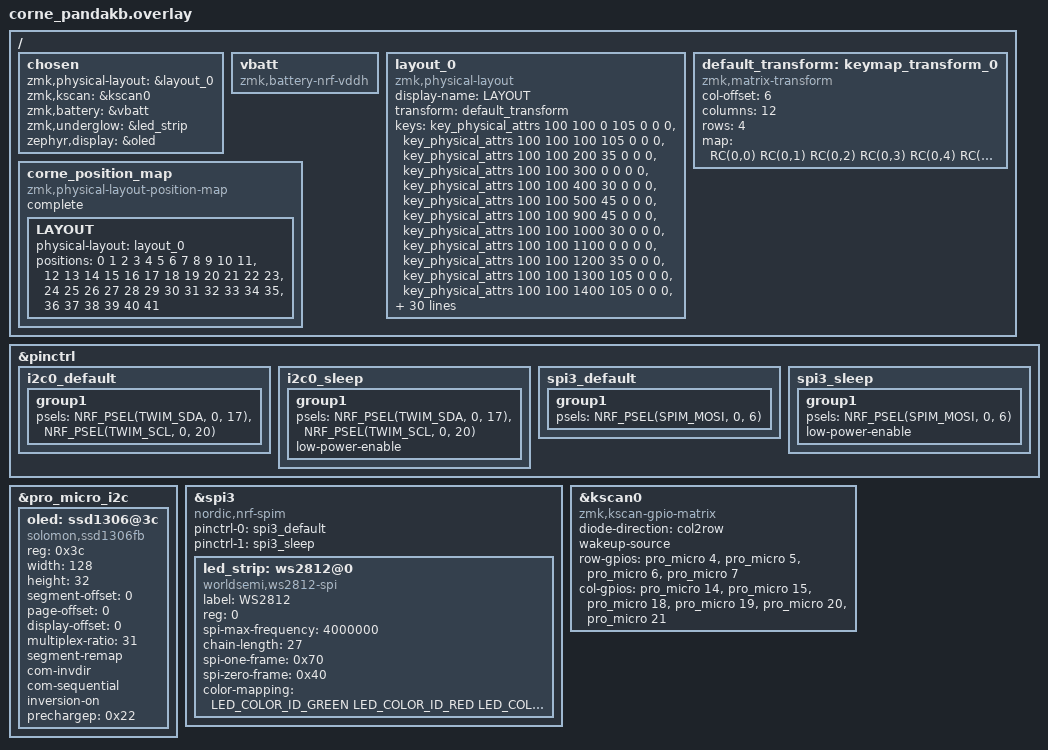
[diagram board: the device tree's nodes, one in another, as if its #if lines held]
#include <dt-bindings/zmk/matrix_transform.h>
#include <dt-bindings/led/led.h>

#ifdef SHIELD_CORNE_LEFT || SHIELD_CORNE_RIGHT
// oled,I2c
&pinctrl {
	i2c0_default: i2c0_default {
		group1 {
			psels = <NRF_PSEL(TWIM_SDA, 0, 17)>,
				<NRF_PSEL(TWIM_SCL, 0, 20)>;
		};
	};

	i2c0_sleep: i2c0_sleep {
		group1 {
			psels = <NRF_PSEL(TWIM_SDA, 0, 17)>,
				<NRF_PSEL(TWIM_SCL, 0, 20)>;
				low-power-enable;
		};
	};
};


&pro_micro_i2c {
	status = "okay";

	oled: ssd1306@3c {
		compatible = "solomon,ssd1306fb";
		reg = <0x3c>;
		width = <128>;
		height = <32>;
		segment-offset = <0>;
		page-offset = <0>;
		display-offset = <0>;
		multiplex-ratio = <31>;
		segment-remap;
		com-invdir;
		com-sequential;
		inversion-on;
		prechargep = <0x22>;
	};
};

// rgb,SPI
&pinctrl {
	spi3_default: spi3_default {
		group1 {
			psels = <NRF_PSEL(SPIM_MOSI, 0, 6)>;
		};
	};

	spi3_sleep: spi3_sleep {
		group1 {
			psels = <NRF_PSEL(SPIM_MOSI, 0, 6)>;
			low-power-enable;
		};
	};
};

&spi3 {
	compatible = "nordic,nrf-spim";
	status = "okay";

	pinctrl-0 = <&spi3_default>;
	pinctrl-1 = <&spi3_sleep>;
	pinctrl-names = "default", "sleep";


	led_strip: ws2812@0 {
		compatible = "worldsemi,ws2812-spi";
		label = "WS2812";

		/* SPI */
		reg = <0>; /* ignored, but necessary for SPI bindings */
		spi-max-frequency = <4000000>;

		/* WS2812 */
		chain-length = <27>; /* There are per-key RGB, but the first 6 are underglow */
		spi-one-frame = <0x70>;
		spi-zero-frame = <0x40>;
		color-mapping = <LED_COLOR_ID_GREEN LED_COLOR_ID_RED LED_COLOR_ID_BLUE>;
	};
};

&kscan0 {
	compatible = "zmk,kscan-gpio-matrix";
	diode-direction = "col2row";
	wakeup-source;

	row-gpios
	= <&pro_micro 4 (GPIO_ACTIVE_HIGH | GPIO_PULL_DOWN)>
	, <&pro_micro 5 (GPIO_ACTIVE_HIGH | GPIO_PULL_DOWN)>
	, <&pro_micro 6 (GPIO_ACTIVE_HIGH | GPIO_PULL_DOWN)>
	, <&pro_micro 7 (GPIO_ACTIVE_HIGH | GPIO_PULL_DOWN)>
	;

#ifdef SHIELD_CORNE_LEFT
	col-gpios
		= <&pro_micro 21 GPIO_ACTIVE_HIGH>
		, <&pro_micro 20 GPIO_ACTIVE_HIGH>
		, <&pro_micro 19 GPIO_ACTIVE_HIGH>
		, <&pro_micro 18 GPIO_ACTIVE_HIGH>
		, <&pro_micro 15 GPIO_ACTIVE_HIGH>
		, <&pro_micro 14 GPIO_ACTIVE_HIGH>
		;
#endif
#ifdef SHIELD_CORNE_RIGHT
	col-gpios
		= <&pro_micro 14	GPIO_ACTIVE_HIGH>
		, <&pro_micro 15	GPIO_ACTIVE_HIGH>
		, <&pro_micro 18	GPIO_ACTIVE_HIGH>
		, <&pro_micro 19	GPIO_ACTIVE_HIGH>
		, <&pro_micro 20	GPIO_ACTIVE_HIGH>
		, <&pro_micro 21	GPIO_ACTIVE_HIGH>
		;
#endif
};
#endif


/ {
	chosen {
		zmk,physical-layout = &layout_0;
#ifdef SHIELD_CORNE_LEFT || SHIELD_CORNE_RIGHT
		zmk,kscan = &kscan0;
		zmk,battery = &vbatt;
		zmk,underglow = &led_strip;
		zephyr,display = &oled;
#endif
	};

	vbatt: vbatt {
		compatible = "zmk,battery-nrf-vddh";
	};

	layout_0: layout_0 {
		compatible = "zmk,physical-layout";
		display-name = "LAYOUT";
		transform = <&default_transform>;

		keys  //                     w   h    x    y     rot    rx    ry
		= <&key_physical_attrs 100 100    0  105       0     0     0>
		, <&key_physical_attrs 100 100  100  105       0     0     0>
		, <&key_physical_attrs 100 100  200   35       0     0     0>
		, <&key_physical_attrs 100 100  300    0       0     0     0>
		, <&key_physical_attrs 100 100  400   30       0     0     0>
		, <&key_physical_attrs 100 100  500   45       0     0     0>
		, <&key_physical_attrs 100 100  900   45       0     0     0>
		, <&key_physical_attrs 100 100 1000   30       0     0     0>
		, <&key_physical_attrs 100 100 1100    0       0     0     0>
		, <&key_physical_attrs 100 100 1200   35       0     0     0>
		, <&key_physical_attrs 100 100 1300  105       0     0     0>
		, <&key_physical_attrs 100 100 1400  105       0     0     0>
		, <&key_physical_attrs 100 100    0  205       0     0     0>
		, <&key_physical_attrs 100 100  100  205       0     0     0>
		, <&key_physical_attrs 100 100  200  135       0     0     0>
		, <&key_physical_attrs 100 100  300  100       0     0     0>
		, <&key_physical_attrs 100 100  400  130       0     0     0>
		, <&key_physical_attrs 100 100  500  145       0     0     0>
		, <&key_physical_attrs 100 100  900  145       0     0     0>
		, <&key_physical_attrs 100 100 1000  130       0     0     0>
		, <&key_physical_attrs 100 100 1100  100       0     0     0>
		, <&key_physical_attrs 100 100 1200  135       0     0     0>
		, <&key_physical_attrs 100 100 1300  205       0     0     0>
		, <&key_physical_attrs 100 100 1400  205       0     0     0>
		, <&key_physical_attrs 100 100    0  305       0     0     0>
		, <&key_physical_attrs 100 100  100  305       0     0     0>
		, <&key_physical_attrs 100 100  200  235       0     0     0>
		, <&key_physical_attrs 100 100  300  200       0     0     0>
		, <&key_physical_attrs 100 100  400  230       0     0     0>
		, <&key_physical_attrs 100 100  500  245       0     0     0>
		, <&key_physical_attrs 100 100  900  245       0     0     0>
		, <&key_physical_attrs 100 100 1000  230       0     0     0>
		, <&key_physical_attrs 100 100 1100  200       0     0     0>
		, <&key_physical_attrs 100 100 1200  235       0     0     0>
		, <&key_physical_attrs 100 100 1300  305       0     0     0>
		, <&key_physical_attrs 100 100 1400  305       0     0     0>
		, <&key_physical_attrs 100 100  390  340       0     0     0>
		, <&key_physical_attrs 100 100  490  340    1300     0   425>
		, <&key_physical_attrs 100 100  590  360    2600     0   460>
		, <&key_physical_attrs 100 100  815  340 (-2600)   950   460>
		, <&key_physical_attrs 100 100  905  330 (-1300)  1050   425>
		, <&key_physical_attrs 100 100 1010  340       0     0     0>
		;
	};

	default_transform: keymap_transform_0 {
		compatible = "zmk,matrix-transform";
#ifdef SHIELD_CORNE_RIGHT
		col-offset = <6>;
#endif
		columns = <12>;
		rows = <4>;
// | SW1  | SW2  | SW3  | SW4  | SW5  | SW6  |   | SW6  | SW5  | SW4  | SW3  | SW2  | SW1  |
// | SW7  | SW8  | SW9  | SW10 | SW11 | SW12 |   | SW12 | SW11 | SW10 | SW9  | SW8  | SW7  |
// | SW13 | SW14 | SW15 | SW16 | SW17 | SW18 |   | SW18 | SW17 | SW16 | SW15 | SW14 | SW13 |
//                      | SW19 | SW20 | SW21 |   | SW21 | SW20 | SW19 |
		map = <
RC(0,0) RC(0,1) RC(0,2) RC(0,3) RC(0,4) RC(0,5)  RC(0,6)  RC(0,7) RC(0,8) RC(0,9) RC(0,10) RC(0,11)
RC(1,0) RC(1,1) RC(1,2) RC(1,3) RC(1,4) RC(1,5)  RC(1,6)  RC(1,7) RC(1,8) RC(1,9) RC(1,10) RC(1,11)
RC(2,0) RC(2,1) RC(2,2) RC(2,3) RC(2,4) RC(2,5)  RC(2,6)  RC(2,7) RC(2,8) RC(2,9) RC(2,10) RC(2,11)
                        RC(3,3) RC(3,4) RC(3,5)  RC(3,6) RC(3,7) RC(3,8)
		>;
	};

	corne_position_map {
		compatible = "zmk,physical-layout-position-map";
		complete;

		LAYOUT {
			physical-layout = <&layout_0>;
			positions
			= < 0  1  2  3  4  5  6  7  8  9 10 11>
			, <12 13 14 15 16 17 18 19 20 21 22 23>
			, <24 25 26 27 28 29 30 31 32 33 34 35>
			, <         36 37 38 39 40 41         >;
		};
	};
};

